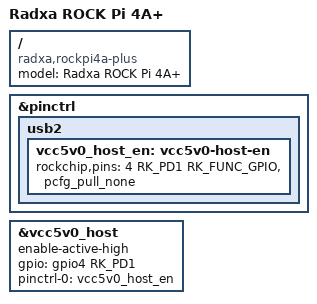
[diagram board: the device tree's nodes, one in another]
// SPDX-License-Identifier: (GPL-2.0+ OR MIT)
/*
 * Copyright (c) 2019 Akash Gajjar <Akash_Gajjar@mentor.com>
 * Copyright (c) 2019 Pragnesh Patel <Pragnesh_Patel@mentor.com>
 */

/dts-v1/;
#include "rk3399-rock-pi-4.dtsi"
#include "rk3399-op1-opp.dtsi"

/ {
	model = "Radxa ROCK Pi 4A+";
	compatible = "radxa,rockpi4a-plus", "radxa,rockpi4", "rockchip,rk3399";
};

&pinctrl {
	usb2 {
		vcc5v0_host_en: vcc5v0-host-en {
			rockchip,pins = <4 RK_PD1 RK_FUNC_GPIO &pcfg_pull_none>;
		};
	};
};

&vcc5v0_host {
	enable-active-high;
	gpio = <&gpio4 RK_PD1 GPIO_ACTIVE_HIGH>;
	pinctrl-names = "default";
	pinctrl-0 = <&vcc5v0_host_en>;
};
